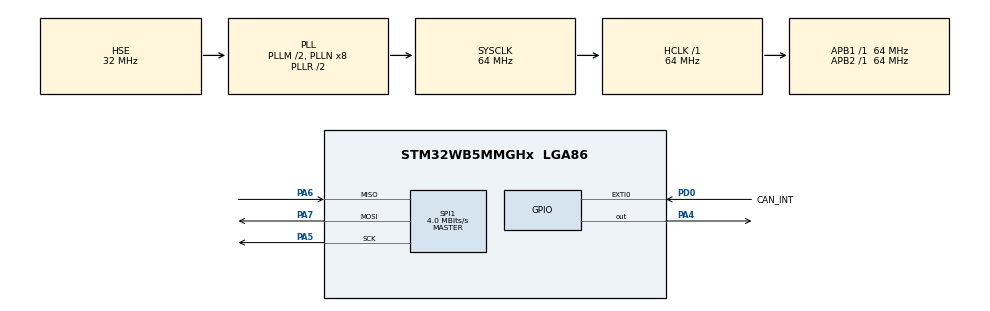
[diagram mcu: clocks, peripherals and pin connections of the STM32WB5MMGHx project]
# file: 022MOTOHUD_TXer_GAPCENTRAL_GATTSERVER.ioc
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Dma.Request0=SPI1_RX
Dma.Request1=SPI1_TX
Dma.SPI1_RX.0.Direction=DMA_PERIPH_TO_MEMORY
Dma.SPI1_RX.0.EventEnable=DISABLE
Dma.SPI1_RX.0.Instance=DMA1_Channel1
Dma.SPI1_RX.0.MemDataAlignment=DMA_MDATAALIGN_BYTE
Dma.SPI1_RX.0.MemInc=DMA_MINC_ENABLE
Dma.SPI1_RX.0.Mode=DMA_NORMAL
Dma.SPI1_RX.0.PeriphDataAlignment=DMA_PDATAALIGN_BYTE
Dma.SPI1_RX.0.PeriphInc=DMA_PINC_DISABLE
Dma.SPI1_RX.0.Polarity=HAL_DMAMUX_REQ_GEN_RISING
Dma.SPI1_RX.0.Priority=DMA_PRIORITY_MEDIUM
Dma.SPI1_RX.0.RequestNumber=1
Dma.SPI1_RX.0.SignalID=NONE
Dma.SPI1_RX.0.SyncEnable=DISABLE
Dma.SPI1_RX.0.SyncPolarity=HAL_DMAMUX_SYNC_NO_EVENT
Dma.SPI1_RX.0.SyncRequestNumber=1
Dma.SPI1_RX.0.SyncSignalID=NONE
Dma.SPI1_TX.1.Direction=DMA_MEMORY_TO_PERIPH
Dma.SPI1_TX.1.EventEnable=DISABLE
Dma.SPI1_TX.1.Instance=DMA1_Channel2
Dma.SPI1_TX.1.MemDataAlignment=DMA_MDATAALIGN_BYTE
Dma.SPI1_TX.1.MemInc=DMA_MINC_ENABLE
Dma.SPI1_TX.1.Mode=DMA_NORMAL
Dma.SPI1_TX.1.PeriphDataAlignment=DMA_PDATAALIGN_BYTE
Dma.SPI1_TX.1.PeriphInc=DMA_PINC_DISABLE
Dma.SPI1_TX.1.Polarity=HAL_DMAMUX_REQ_GEN_RISING
Dma.SPI1_TX.1.Priority=DMA_PRIORITY_MEDIUM
Dma.SPI1_TX.1.RequestNumber=1
Dma.SPI1_TX.1.SignalID=NONE
Dma.SPI1_TX.1.SyncEnable=DISABLE
Dma.SPI1_TX.1.SyncPolarity=HAL_DMAMUX_SYNC_NO_EVENT
Dma.SPI1_TX.1.SyncRequestNumber=1
Dma.SPI1_TX.1.SyncSignalID=NONE
Mcu.Family=STM32WB
Mcu.Name=STM32WB5MMGHx
Mcu.Package=LGA86
NVIC.DMA1_Channel1_IRQn=true\:0\:0\:false\:false\:true\:false\:true\:true
NVIC.DMA1_Channel2_IRQn=true\:0\:0\:false\:false\:true\:false\:true\:true
NVIC.EXTI0_IRQn=true\:0\:0\:false\:false\:true\:true\:true\:true
NVIC.HSEM_IRQn=true\:0\:0\:false\:false\:true\:false\:true\:true
NVIC.PriorityGroup=NVIC_PRIORITYGROUP_4
PA4.GPIO_ModeDefaultOutputPP=GPIO_MODE_OUTPUT_PP
PA4.GPIO_Speed=GPIO_SPEED_FREQ_HIGH
PA4.PinState=GPIO_PIN_SET
PA4.Signal=GPIO_Output
PA5.Mode=Full_Duplex_Master
PA5.Signal=SPI1_SCK
PA6.Mode=Full_Duplex_Master
PA6.Signal=SPI1_MISO
PA7.Mode=Full_Duplex_Master
PA7.Signal=SPI1_MOSI
PD0.GPIO_Label=CAN_INT
PD0.GPIO_ModeDefaultEXTI=GPIO_MODE_IT_FALLING
PD0.GPIO_PuPd=GPIO_PULLUP
PD0.Signal=GPXTI0
ProjectManager.HeapSize=0x200
ProjectManager.StackSize=0x400
ProjectManager.TargetToolchain=STM32CubeIDE
RCC.ADCFreq_Value=64000000
RCC.AHB2CLKDivider=RCC_SYSCLK_DIV2
RCC.AHBFreq_Value=64000000
RCC.APB1Freq_Value=64000000
RCC.APB1TimFreq_Value=64000000
RCC.APB2Freq_Value=64000000
RCC.APB2TimFreq_Value=64000000
RCC.APB3Freq_Value=16000000
RCC.Cortex2_Div=SYSTICK_CLKSOURCE_HCLK_DIV8
RCC.CortexFreq_Value=64000000
RCC.HCLKFreq_Value=64000000
RCC.HSE_VALUE=32000000
RCC.HSI48_VALUE=48000000
RCC.HSI_VALUE=16000000
RCC.PLLM=RCC_PLLM_DIV2
RCC.PLLSourceVirtual=RCC_PLLSOURCE_HSE
RCC.SMPSCLockSelection=RCC_SMPSCLKSOURCE_HSE
RCC.SMPSDivider=4
RCC.SYSCLKFreq_VALUE=64000000
RCC.SYSCLKSource=RCC_SYSCLKSOURCE_PLLCLK
RCC.USBFreq_Value=64000000
RCC.VCOOutputFreq_Value=128000000
SPI1.BaudRatePrescaler=SPI_BAUDRATEPRESCALER_16
SPI1.CLKPhase=SPI_PHASE_2EDGE
SPI1.CLKPolarity=SPI_POLARITY_HIGH
SPI1.CalculateBaudRate=4.0 MBits/s
SPI1.DataSize=SPI_DATASIZE_8BIT
SPI1.Direction=SPI_DIRECTION_2LINES
SPI1.Mode=SPI_MODE_MASTER
SPI1.TIMode=SPI_TIMODE_DISABLE
SPI1.VirtualType=VM_MASTER
VP_HSEM_VS_HSEM.Mode=HSEM_Activate
VP_IPCC_VS_IPCC.Mode=IPCC_Activate
VP_MEMORYMAP_VS_MEMORYMAP.Mode=CurAppReg
VP_RCC_V_OSC32_IN.Mode=LSE-External-Clock-Source
VP_RCC_V_OSC_IN.Mode=HSE-External-Clock-Source
VP_RTC_VS_RTC_Activate.Mode=RTC_Enabled
VP_RTC_VS_RTC_WakeUp_intern.Mode=WakeUp
board=custom

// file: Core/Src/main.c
/* USER CODE BEGIN Header */
/**
 ******************************************************************************
 * @file           : main.c
 * @brief          : Main program body
 ******************************************************************************
 * @attention
 *
 * Copyright (c) 2025 STMicroelectronics.
 * All rights reserved.
 *
 * This software is licensed under terms that can be found in the LICENSE file
 * in the root directory of this software component.
 * If no LICENSE file comes with this software, it is provided AS-IS.
 *
 ******************************************************************************
 */
/* USER CODE END Header */
#include "main.h"

/* USER CODE BEGIN Includes */
#include "mcp2515_driver.h"
/* USER CODE END Includes */

IPCC_HandleTypeDef hipcc;

RTC_HandleTypeDef hrtc;

SPI_HandleTypeDef hspi1;
DMA_HandleTypeDef hdma_spi1_rx;
DMA_HandleTypeDef hdma_spi1_tx;

void SystemClock_Config(void);
void PeriphCommonClock_Config(void);
static void MX_GPIO_Init(void);
static void MX_DMA_Init(void);
static void MX_IPCC_Init(void);
static void MX_RTC_Init(void);
static void MX_SPI1_Init(void);

/* USER CODE BEGIN 0 */
uint8_t RxBuffer[8] = {0};

/* USER CODE END 0 */

int main(void)
{

  /* MCU Configuration--------------------------------------------------------*/

  /* Reset of all peripherals, Initializes the Flash interface and the Systick. */
  HAL_Init();

  /* Configure the system clock */
  SystemClock_Config();

  /* Configure the peripherals common clocks */
  PeriphCommonClock_Config();

  /* IPCC initialisation */
  MX_IPCC_Init();

  /* Initialize all configured peripherals */
  MX_GPIO_Init();
  MX_DMA_Init();
  MX_RTC_Init();
  MX_SPI1_Init();
  /* USER CODE BEGIN 2 */
	MCP2515_SPI_Reset();

	MCP2515_SPI_ReadStatus(RxBuffer, 1);

	MCP2515_SPI_ReadRegister(CANCTRL_ADDR_BTM, RxBuffer, 2);

	MCP2515_SPI_ReadRegister(RXF3SIDH_ADDR, RxBuffer, 1);

	MCP2515_SPI_BitModify(, maskByte, dataByte)

  /* USER CODE END 2 */

  /* Infinite loop */
	while (1)
	{

	}
}

void SystemClock_Config(void)
{
  RCC_OscInitTypeDef RCC_OscInitStruct = {0};
  RCC_ClkInitTypeDef RCC_ClkInitStruct = {0};

  /** Configure the main internal regulator output voltage
  */
  __HAL_PWR_VOLTAGESCALING_CONFIG(PWR_REGULATOR_VOLTAGE_SCALE1);

  /** Initializes the RCC Oscillators according to the specified parameters
  * in the RCC_OscInitTypeDef structure.
  */
  RCC_OscInitStruct.OscillatorType = RCC_OSCILLATORTYPE_HSI|RCC_OSCILLATORTYPE_LSI1
                              |RCC_OSCILLATORTYPE_HSE;
  RCC_OscInitStruct.HSEState = RCC_HSE_ON;
  RCC_OscInitStruct.HSIState = RCC_HSI_ON;
  RCC_OscInitStruct.HSICalibrationValue = RCC_HSICALIBRATION_DEFAULT;
  RCC_OscInitStruct.LSIState = RCC_LSI_ON;
  RCC_OscInitStruct.PLL.PLLState = RCC_PLL_ON;
  RCC_OscInitStruct.PLL.PLLSource = RCC_PLLSOURCE_HSE;
  RCC_OscInitStruct.PLL.PLLM = RCC_PLLM_DIV2;
  RCC_OscInitStruct.PLL.PLLN = 8;
  RCC_OscInitStruct.PLL.PLLP = RCC_PLLP_DIV2;
  RCC_OscInitStruct.PLL.PLLR = RCC_PLLR_DIV2;
  RCC_OscInitStruct.PLL.PLLQ = RCC_PLLQ_DIV2;
  if (HAL_RCC_OscConfig(&RCC_OscInitStruct) != HAL_OK)
  {
    Error_Handler();
  }

  /** Configure the SYSCLKSource, HCLK, PCLK1 and PCLK2 clocks dividers
  */
  RCC_ClkInitStruct.ClockType = RCC_CLOCKTYPE_HCLK4|RCC_CLOCKTYPE_HCLK2
                              |RCC_CLOCKTYPE_HCLK|RCC_CLOCKTYPE_SYSCLK
                              |RCC_CLOCKTYPE_PCLK1|RCC_CLOCKTYPE_PCLK2;
  RCC_ClkInitStruct.SYSCLKSource = RCC_SYSCLKSOURCE_PLLCLK;
  RCC_ClkInitStruct.AHBCLKDivider = RCC_SYSCLK_DIV1;
  RCC_ClkInitStruct.APB1CLKDivider = RCC_HCLK_DIV1;
  RCC_ClkInitStruct.APB2CLKDivider = RCC_HCLK_DIV1;
  RCC_ClkInitStruct.AHBCLK2Divider = RCC_SYSCLK_DIV2;
  RCC_ClkInitStruct.AHBCLK4Divider = RCC_SYSCLK_DIV1;

  if (HAL_RCC_ClockConfig(&RCC_ClkInitStruct, FLASH_LATENCY_3) != HAL_OK)
  {
    Error_Handler();
  }
}

void PeriphCommonClock_Config(void)
{
  RCC_PeriphCLKInitTypeDef PeriphClkInitStruct = {0};

  /** Initializes the peripherals clock
  */
  PeriphClkInitStruct.PeriphClockSelection = RCC_PERIPHCLK_SMPS;
  PeriphClkInitStruct.SmpsClockSelection = RCC_SMPSCLKSOURCE_HSE;
  PeriphClkInitStruct.SmpsDivSelection = RCC_SMPSCLKDIV_RANGE1;

  if (HAL_RCCEx_PeriphCLKConfig(&PeriphClkInitStruct) != HAL_OK)
  {
    Error_Handler();
  }
}

static void MX_IPCC_Init(void)
{

  hipcc.Instance = IPCC;
  if (HAL_IPCC_Init(&hipcc) != HAL_OK)
  {
    Error_Handler();
  }

}

static void MX_RTC_Init(void)
{

  /** Initialize RTC Only
  */
  hrtc.Instance = RTC;
  hrtc.Init.HourFormat = RTC_HOURFORMAT_24;
  hrtc.Init.AsynchPrediv = 127;
  hrtc.Init.SynchPrediv = 255;
  hrtc.Init.OutPut = RTC_OUTPUT_DISABLE;
  hrtc.Init.OutPutPolarity = RTC_OUTPUT_POLARITY_HIGH;
  hrtc.Init.OutPutType = RTC_OUTPUT_TYPE_OPENDRAIN;
  hrtc.Init.OutPutRemap = RTC_OUTPUT_REMAP_NONE;
  if (HAL_RTC_Init(&hrtc) != HAL_OK)
  {
    Error_Handler();
  }

  /** Enable the WakeUp
  */
  if (HAL_RTCEx_SetWakeUpTimer(&hrtc, 0, RTC_WAKEUPCLOCK_RTCCLK_DIV16) != HAL_OK)
  {
    Error_Handler();
  }

}

static void MX_SPI1_Init(void)
{

  /* SPI1 parameter configuration*/
  hspi1.Instance = SPI1;
  hspi1.Init.Mode = SPI_MODE_MASTER;
  hspi1.Init.Direction = SPI_DIRECTION_2LINES;
  hspi1.Init.DataSize = SPI_DATASIZE_8BIT;
  hspi1.Init.CLKPolarity = SPI_POLARITY_HIGH;
  hspi1.Init.CLKPhase = SPI_PHASE_2EDGE;
  hspi1.Init.NSS = SPI_NSS_SOFT;
  hspi1.Init.BaudRatePrescaler = SPI_BAUDRATEPRESCALER_16;
  hspi1.Init.FirstBit = SPI_FIRSTBIT_MSB;
  hspi1.Init.TIMode = SPI_TIMODE_DISABLE;
  hspi1.Init.CRCCalculation = SPI_CRCCALCULATION_DISABLE;
  hspi1.Init.CRCPolynomial = 7;
  hspi1.Init.CRCLength = SPI_CRC_LENGTH_DATASIZE;
  hspi1.Init.NSSPMode = SPI_NSS_PULSE_DISABLE;
  if (HAL_SPI_Init(&hspi1) != HAL_OK)
  {
    Error_Handler();
  }

}

static void MX_DMA_Init(void)
{

  /* DMA controller clock enable */
  __HAL_RCC_DMAMUX1_CLK_ENABLE();
  __HAL_RCC_DMA1_CLK_ENABLE();

  /* DMA interrupt init */
  /* DMA1_Channel1_IRQn interrupt configuration */
  HAL_NVIC_SetPriority(DMA1_Channel1_IRQn, 0, 0);
  HAL_NVIC_EnableIRQ(DMA1_Channel1_IRQn);
  /* DMA1_Channel2_IRQn interrupt configuration */
  HAL_NVIC_SetPriority(DMA1_Channel2_IRQn, 0, 0);
  HAL_NVIC_EnableIRQ(DMA1_Channel2_IRQn);
  /* DMAMUX1_OVR_IRQn interrupt configuration */
  HAL_NVIC_SetPriority(DMAMUX1_OVR_IRQn, 0, 0);
  HAL_NVIC_EnableIRQ(DMAMUX1_OVR_IRQn);

}

static void MX_GPIO_Init(void)
{
  GPIO_InitTypeDef GPIO_InitStruct = {0};

  /* GPIO Ports Clock Enable */
  __HAL_RCC_GPIOD_CLK_ENABLE();
  __HAL_RCC_GPIOA_CLK_ENABLE();

  /*Configure GPIO pin Output Level */
  HAL_GPIO_WritePin(GPIOA, GPIO_PIN_4, GPIO_PIN_SET);

  /*Configure GPIO pin : CAN_INT_Pin */
  GPIO_InitStruct.Pin = CAN_INT_Pin;
  GPIO_InitStruct.Mode = GPIO_MODE_IT_FALLING;
  GPIO_InitStruct.Pull = GPIO_PULLUP;
  HAL_GPIO_Init(CAN_INT_GPIO_Port, &GPIO_InitStruct);

  /*Configure GPIO pin : PA4 */
  GPIO_InitStruct.Pin = GPIO_PIN_4;
  GPIO_InitStruct.Mode = GPIO_MODE_OUTPUT_PP;
  GPIO_InitStruct.Pull = GPIO_NOPULL;
  GPIO_InitStruct.Speed = GPIO_SPEED_FREQ_HIGH;
  HAL_GPIO_Init(GPIOA, &GPIO_InitStruct);

  /* EXTI interrupt init*/
  HAL_NVIC_SetPriority(EXTI0_IRQn, 0, 0);
  HAL_NVIC_EnableIRQ(EXTI0_IRQn);

}

void Error_Handler(void)
{
	__disable_irq();
	while (1)
	{
	}
}
